# pktdma_flo register map
Vendor: Texas Instruments
Peripheral module from a debugger description file (folder pktdma).
Registers are 32-bit, write-only, no defined reset value unless marked. A register's access mark holds for its fields unless they carry their own. Offsets are as the file gives them; lines under a group give offsets from that group; [hi:lo] are bit positions; {n}, {i} and the like mark numbered series; 'fields as' and 'values as' point back to an identical list; <NAME> marks a mode.

## SRIO_PKTDMA_RX_FLO
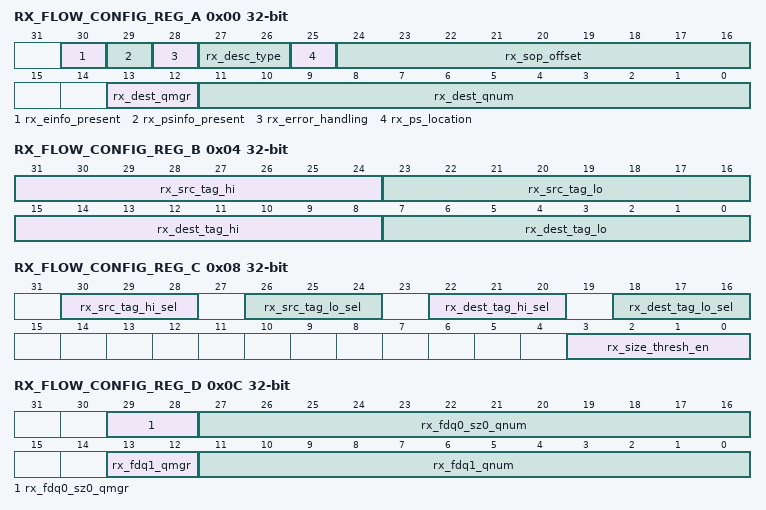
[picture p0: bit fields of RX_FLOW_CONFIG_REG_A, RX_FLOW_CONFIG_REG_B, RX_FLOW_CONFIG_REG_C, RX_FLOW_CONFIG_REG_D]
0x00 RX_FLOW_CONFIG_REG_A — (1 of 129, stride 32)
  [30] rx_einfo_present — Rx extended packet info block present
  [29] rx_psinfo_present — Rx protocol specific words present
  [28] rx_error_handling — Rx error handling mode
  [27:26] rx_desc_type — Rx descriptor type
  [25] rx_ps_location — Rx protocol specific location
  [24:16] rx_sop_offset — Rx start of packet offset
  [13:12] rx_dest_qmgr — Rx destination queue manager
  [11:0] rx_dest_qnum — Rx destination queue
0x04 RX_FLOW_CONFIG_REG_B ro — (1 of 129, stride 32)
  [31:24] rx_src_tag_hi — Rx source tag high byte constant value
  [23:16] rx_src_tag_lo — Rx source tag low byte constant value
  [15:8] rx_dest_tag_hi — Rx destination tag high byte constant value
  [7:0] rx_dest_tag_lo — Rx destination tag low byte constant value
0x08 RX_FLOW_CONFIG_REG_C — (1 of 129, stride 32)
  [30:28] rx_src_tag_hi_sel — Rx source tag high byte selector
  [26:24] rx_src_tag_lo_sel — Rx source tag low byte selector
  [22:20] rx_dest_tag_hi_sel — Rx destination tag high byte selector
  [18:16] rx_dest_tag_lo_sel — Rx destination tag low byte selector
  [3:0] rx_size_thresh_en — Rx packet sized based free buffer queue enables
0x0C RX_FLOW_CONFIG_REG_D — (1 of 129, stride 32)
  [29:28] rx_fdq0_sz0_qmgr — Rx free descriptor 0 queue manager index
  [27:16] rx_fdq0_sz0_qnum — Rx free descriptor 0 queue index
  [13:12] rx_fdq1_qmgr — Rx free descriptor 1 queue manager index
  [11:0] rx_fdq1_qnum — Rx free descriptor 1 queue index
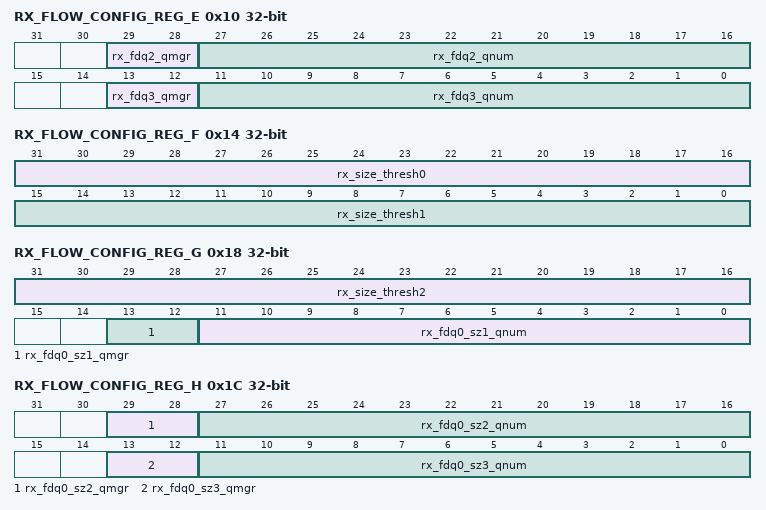
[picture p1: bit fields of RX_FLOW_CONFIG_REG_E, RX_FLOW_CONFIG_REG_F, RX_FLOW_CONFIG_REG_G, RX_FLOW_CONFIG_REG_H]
0x10 RX_FLOW_CONFIG_REG_E — (1 of 129, stride 32)
  [29:28] rx_fdq2_qmgr — Rx free descriptor 2 queue manager index
  [27:16] rx_fdq2_qnum — Rx free descriptor 2 queue index
  [13:12] rx_fdq3_qmgr — Rx free descriptor 3 queue manager index
  [11:0] rx_fdq3_qnum — Rx free descriptor 3 queue index
0x14 RX_FLOW_CONFIG_REG_F — (1 of 129, stride 32)
  [31:16] rx_size_thresh0 — Rx packet size threshold 0
  [15:0] rx_size_thresh1 — Rx packet size threshold 1
0x18 RX_FLOW_CONFIG_REG_G — (1 of 129, stride 32)
  [31:16] rx_size_thresh2 — Rx packet size threshold 2
  [13:12] rx_fdq0_sz1_qmgr — Rx free descriptor 0 queue manager index
  [11:0] rx_fdq0_sz1_qnum — Rx free descriptor 0 queue index
0x1C RX_FLOW_CONFIG_REG_H — (1 of 129, stride 32)
  [29:28] rx_fdq0_sz2_qmgr — Rx free descriptor 0 queue manager index
  [27:16] rx_fdq0_sz2_qnum — Rx free descriptor 0 queue index
  [13:12] rx_fdq0_sz3_qmgr — Rx free descriptor 0 queue manager index
  [11:0] rx_fdq0_sz3_qnum — Rx free descriptor 0 queue index
